# uart_16550_main: IP-XACT component
VLNV tenstorrent.com:ocah:uart_16550_main:1.0

## Address spaces and blocks
uart_16550_main_mmap.uart_16550_main: base 'h0, range 'h28, width 32

## Registers
Registers are 32-bit, read-write, reset 0x0 unless marked. A register's access mark holds for its fields unless they carry their own. Offsets are from the block's base; lines under a group give offsets from that group; [hi:lo] are bit positions; {n}, {i} and the like mark numbered series; 'fields as' and 'values as' point back to an identical list; <NAME> marks a mode.

## uart_16550_main_mmap.uart_16550_main — Contains the mode-independent registers and the read-only registers accessible only when `DLAB = 0`.
Base 0x00000000
0x00 RBR ro — Receiver Buffer Register
  [7:0] DATA read-modifies — Received Data. Contains a received character. If FIFOs are enabled, this field points to the bottom of the RX FIFO. Otherwise, this field points to a single- byte Receiver Buffer Register.
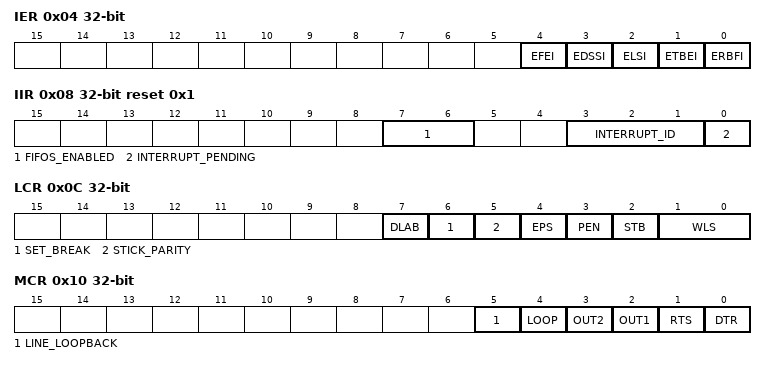
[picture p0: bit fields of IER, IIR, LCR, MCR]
0x04 IER — Interrupt Enable Register
  [4] EFEI — Enable FIFO Error Interrupt.
  [3] EDSSI — Enable (Delta Status of) Modem Status Interrupt.
  [2] ELSI — Enable (Receiver) Line Status Interrupt.
  [1] ETBEI — Enable Transmitter Buffer Empty (Transmitter Holding Register Empty) Interrupt.
  [0] ERBFI — Enable Receiver Buffer Full (Received Data Ready) Interrupt.
0x08 IIR ro reset 0x1 — Interrupt Identification Register
  [7:6] FIFOS_ENABLED — FIFOs Enabled: * `0x0` - FIFOs are disabled * `0x3` - FIFOs are enabled
  [3:1] INTERRUPT_ID — Interrupt ID: * `0x7` - FIFO Error Interrupt (priority 0) * `0x3` - Receiver Line Status Interrupt (priority 1) * `0x6` - Reception Timeout Interrupt (priority 2) * `0x2` - Received Data Ready Interrupt (priority 3) * `0x1` - Transmitter Holding Register Empty Interrupt (priority 4) * `0x0` - Modem Status Interrupt (priority 5)
  [0] INTERRUPT_PENDING — Interrupt Pending. Active-low.
0x0C LCR — Line Control Register
  [7] DLAB — Divisor Latch Access Bit. If set, allows access to the `DLL` and `DLM` registers when accessing addresses `0x0` and `0x4`, respectively. If unset, allows access to the `THR`, `RBR`, and `IER` registers. `IIR` and `FCR` are accessible regardless of this bit.
  [6] SET_BREAK — Set Break. If set, forces the `tx_o` output to `0` to cause a break condition on the receiving UART.
  [5] STICK_PARITY — Stick Parity. If set, forces the transmit and received parity bits to be `0` if even parity is selected and `1` if odd parity is selected.
  [4] EPS — Even Parity Select: * `1` - even parity * `0` - odd parity
  [3] PEN — Parity Enable.
  [2] STB — Stop Bits: * `0` - 1 stop bit. * `1` - 2 stop bits. The transmitter always sends 2 stop bits; with 5-bit words the receiver checks only the first.
  [1:0] WLS — Word Length Select: * `0x0` - 5 bits per character * `0x1` - 6 bits per character * `0x2` - 7 bits per character * `0x3` - 8 bits per character
0x10 MCR — Modem Control Register
  [5] LINE_LOOPBACK — Line Loopback. If set, the `rx_i` input is internally connected to the `tx_o` output.
  [4] LOOP — System Loopback. If set, the transmitter is internally connected to the receiver. The `tx_o` output is set to `1`.
  [3] OUT2 — User Output 2. Writing to this bit drives the `out2_no` in the opposite polarity.
  [2] OUT1 — User Output 1. Writing to this bit drives the `out1_no` in the opposite polarity.
  [1] RTS — Request to Send. Writing to this bit drives the `rts_no` output in the opposite polarity.
  [0] DTR — Data Terminal Ready. Writing to this bit drives the `dtr_no` output in the opposite polarity.
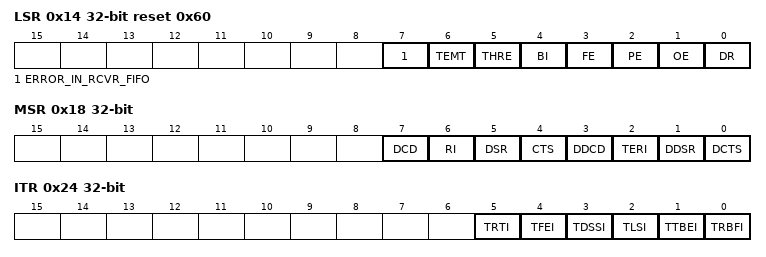
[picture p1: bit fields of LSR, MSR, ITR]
0x14 LSR ro reset 0x60 — Line Status Register
  [7] ERROR_IN_RCVR_FIFO — Error in Receiver FIFO. When set, indicates that the receiver FIFO or (RBR in non-FIFO mode) has the parity, framing, or break error. In other words, at least one of the PE, FE, and BI bits is set.
  [6] TEMT — Transmitter Empty. When set, indicates that the transmitter shift register and the transmitter FIFO (or THR in non-FIFO mode) are empty.
  [5] THRE — Transmitter Holding Register Empty. When set, indicates that the TX FIFO (or THR in non-FIFO mode) is empty. Clearing the Transmitter Holding Register Empty Interrupt does NOT clear this bit.
  [4] BI read-clears — Break Interrupt. When set, indicates that the `rx_i` input is `0` for an entire frame's time (start + data + parity + stop bits). In FIFO mode, this bit set when the character reaches the top of the receiver FIFO. In non-FIFO mode, this bit is set when the character enters the RBR. This bit triggers the Receiver Line Status Interrupt.
  [3] FE read-clears — Framing Error. When set, indicates that the received character is missing a stop bit. In FIFO mode, this bit is set when the character reaches the top of the FIFO. In non-FIFO mode, this bit is set when the character enters the RBR. This bit triggers the Receiver Line Status Interrupt.
  [2] PE read-clears — Parity Error. When set, indicates that the character at the top of the receiver FIFO (or RBR in non-FIFO mode) has a parity error. This bit triggers the Receiver Line Status Interrupt.
  [1] OE read-clears — Overrun Error. When set, indicates that the RX FIFO was full when a new character was received; the new character is dropped. This bit sets only in FIFO mode: in non-FIFO mode a new character overwrites an unread character in the RBR without setting it. This bit triggers the Receiver Line Status Interrupt.
  [0] DR — Data Ready. When set, indicates that the RX FIFO (or RBR in non-FIFO mode) contains data.
0x18 MSR ro — Modem Status Register
  [7] DCD — Data Carrier Detect. This bit reflects the `dcd_ni` input in the opposite polarity, so it reads `1` while a carrier is detected.
  [6] RI — Ring Indicator. This bit reflects the `ri_ni` input in the opposite polarity, so it reads `1` while the remote modem signals an incoming call.
  [5] DSR — Data Set Ready. This bit reflects the `dsr_ni` input in the opposite polarity, so it reads `1` while the remote modem is connected and ready.
  [4] CTS — Clear to Send. This bit reflects the `cts_ni` input in the opposite polarity, so it reads `1` while the remote device is ready to receive data.
  [3] DDCD read-clears — Delta Data Carrier Detect. When set, indicates that the `DCD` bit has changed since the last time this register was read. This bit triggers the Modem Status Interrupt.
  [2] TERI read-clears — Trailing Edge Ring Indicator. When set, indicates that the `RI` bit has changed from a `1` to a `0`. This bit triggers the Modem Status Interrupt.
  [1] DDSR read-clears — Delta Data Set Ready. When set, indicates that the `DSR` bit has changed since the last time this register was read. This bit triggers the Modem Status Interrupt.
  [0] DCTS read-clears — Delta Clear to Send. When set, indicates that the `CTS` bit has changed since the last time this register was read. This bit triggers the Modem Status Interrupt.
0x1C SCR — Scratch Register
  [7:0] SCR — Scratch. Holds user data.
0x20 ECR — Extended Control Register
  [1:0] RCVR_TRIGGER_MS2B — Receiver FIFO Trigger Level Most Significant 2 Bits. To configure the least significant 2 bits, use the `FCR.RCVR_TRIGGER` register field. The configurations for the trigger levels are: * `0x0` - 1 character * `0x1` - 4 characters * `0x2` - 8 characters * `0x3` - 14 characters * `0x4` - 32 characters * `0x5` - 64 characters * `0x6` - 128 characters * `0x7` - 256 characters * `0x8` - 512 characters * `0x9` - 1024 characters * `0xA` - 2048 characters * `0xB` - 4096 characters The Received Data Ready interrupt asserts while the receive FIFO holds at least the selected number of characters. A level above the receive FIFO depth, and any combined value above `0xB`, never asserts it.
0x24 ITR — Interrupt Test Register
  [5] TRTI — Test Reception Timeout Interrupt. Writing a `1` forces the interrupt and writing `0` releases it.
  [4] TFEI — Test FIFO Error Interrupt. Writing `1` forces the interrupt and writing `0` releases it.
  [3] TDSSI — Test (Delta Status of) Modem Status Interrupt. Writing `1` forces the interrupt and writing `0` releases it.
  [2] TLSI — Test (Receiver) Line Status Interrupt. Writing `1` forces the interrupt and writing `0` releases it.
  [1] TTBEI — Test Transmitter Buffer Empty (Transmitter Holding Register Empty) Interrupt. Writing `1` forces the interrupt and writing `0` releases it.
  [0] TRBFI — Test Receiver Buffer Full (Received Data Ready) Interrupt. Writing `1` forces the interrupt and writing `0` releases it.

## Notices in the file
SPDX-License-Identifier: Apache-2.0
SPDX-FileCopyrightText: 2026 Tenstorrent USA, Inc.
